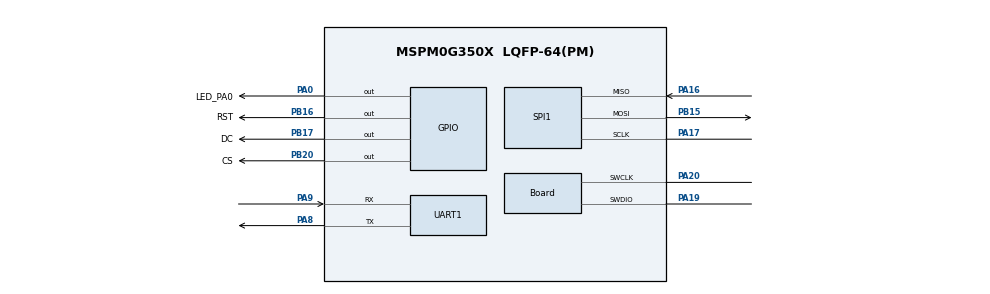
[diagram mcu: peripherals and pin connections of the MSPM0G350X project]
/**
 * @cliArgs --device "MSPM0G350X" --package "LQFP-64(PM)" --part "Default" --product "mspm0_sdk@2.00.01.00"
 * @versions {"tool":"1.20.0+3587"}
 */

/**
 * Import the modules used in this configuration.
 */
const GPIO          = scripting.addModule("/ti/driverlib/GPIO", {}, false);
const GPIO1         = GPIO.addInstance();
const GPIO2         = GPIO.addInstance();
const SPI           = scripting.addModule("/ti/driverlib/SPI", {}, false);
const SPI1          = SPI.addInstance();
const SYSCTL        = scripting.addModule("/ti/driverlib/SYSCTL");
const UART          = scripting.addModule("/ti/driverlib/UART", {}, false);
const UART1         = UART.addInstance();
const ProjectConfig = scripting.addModule("/ti/project_config/ProjectConfig");

/**
 * Write custom configuration values to the imported modules.
 */
GPIO1.port                          = "PORTA";
GPIO1.$name                         = "USER_GPIO";
GPIO1.associatedPins[0].$name       = "LED_PA0";
GPIO1.associatedPins[0].pin.$assign = "PA0";

const Board                       = scripting.addModule("/ti/driverlib/Board", {}, false);
Board.peripheral.$assign          = "DEBUGSS";
Board.peripheral.swclkPin.$assign = "PA20";
Board.peripheral.swdioPin.$assign = "PA19";

GPIO2.$name                         = "PORTB";
GPIO2.associatedPins.create(3);
GPIO2.associatedPins[0].$name       = "RST";
GPIO2.associatedPins[0].pin.$assign = "PB16";
GPIO2.associatedPins[1].$name       = "DC";
GPIO2.associatedPins[1].pin.$assign = "PB17";
GPIO2.associatedPins[2].$name       = "CS";
GPIO2.associatedPins[2].pin.$assign = "PB20";

SPI1.$name                      = "SPI_0";
SPI1.targetBitRate              = 1000000;
SPI1.frameFormat                = "MOTO3";
SPI1.polarity                   = "1";
SPI1.phase                      = "1";
SPI1.peripheral.$assign         = "SPI1";
SPI1.peripheral.sclkPin.$assign = "PA17";
SPI1.peripheral.mosiPin.$assign = "PB15";
SPI1.peripheral.misoPin.$assign = "PA16";
SPI1.sclkPinConfig.$name        = "ti_driverlib_gpio_GPIOPinGeneric2";
SPI1.mosiPinConfig.$name        = "ti_driverlib_gpio_GPIOPinGeneric3";
SPI1.misoPinConfig.$name        = "ti_driverlib_gpio_GPIOPinGeneric4";

SYSCTL.clockTreeEn = true;

UART1.rxFifoThreshold                  = "DL_UART_RX_FIFO_LEVEL_ONE_ENTRY";
UART1.enableDMARX                      = false;
UART1.enableDMATX                      = false;
UART1.uartClkSrc                       = "BUSCLK";
UART1.ovsRate                          = "16";
UART1.enableFIFO                       = true;
UART1.enabledInterrupts                = ["RX"];
UART1.$name                            = "UART_1";
UART1.peripheral.$assign               = "UART1";
UART1.peripheral.rxPin.$assign         = "PA9";
UART1.peripheral.txPin.$assign         = "PA8";
UART1.txPinConfig.$name                = "ti_driverlib_gpio_GPIOPinGeneric0";
UART1.txPinConfig.direction            = scripting.forceWrite("OUTPUT");
UART1.txPinConfig.hideOutputInversion  = scripting.forceWrite(false);
UART1.txPinConfig.onlyInternalResistor = scripting.forceWrite(false);
UART1.txPinConfig.passedPeripheralType = scripting.forceWrite("Digital");
UART1.rxPinConfig.$name                = "ti_driverlib_gpio_GPIOPinGeneric1";
UART1.rxPinConfig.hideOutputInversion  = scripting.forceWrite(false);
UART1.rxPinConfig.onlyInternalResistor = scripting.forceWrite(false);
UART1.rxPinConfig.passedPeripheralType = scripting.forceWrite("Digital");

ProjectConfig.deviceSpin = "MSPM0G3507";
